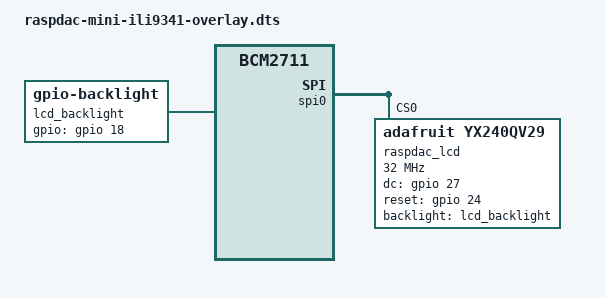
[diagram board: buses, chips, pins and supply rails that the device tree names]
/dts-v1/;
/plugin/;

/*
 * Audiophonics RaspDAC Mini - ILI9341
 * Raspberry Pi 4 / Raspberry Pi OS Trixie / DRM-KMS
 *
 * Wiring assumed:
 *   SPI bus : SPI0
 *   CS      : CE0 / GPIO8
 *   MOSI    : GPIO10
 *   SCLK    : GPIO11
 *   DC      : GPIO27
 *   RESET   : GPIO24
 *
 * Backlight: the LCD "LED" pin is hardwired to 3V3 on the HAT, so there is
 * no software control out of the box. To make it controllable, do the
 * hardware mod: cut the LED->3V3 trace on the HAT and wire the LCD "LED"
 * pin to GPIO18 (physical pin 12). The gpio-backlight node below then
 * creates /sys/class/backlight/lcd_backlight and the DRM core switches the
 * backlight off automatically when the output is blanked (wlopm --off).
 *
 * The in-kernel DRM tiny ILI9341 driver matches "adafruit,yx240qv29".
 * rotation = <90> gives a 320x240 logical landscape display.
 */

/ {
    compatible = "brcm,bcm2711";

    fragment@0 {
        target = <&spi0>;
        __overlay__ {
            status = "okay";

            #address-cells = <1>;
            #size-cells = <0>;

            raspdac_lcd: display@0 {
                compatible = "adafruit,yx240qv29", "ilitek,ili9341";
                reg = <0>;

                spi-max-frequency = <32000000>;

                dc-gpios = <&gpio 27 0>;
                reset-gpios = <&gpio 24 0>;
                backlight = <&lcd_backlight>;

                rotation = <90>;

                status = "okay";
            };
        };
    };

    fragment@1 {
        target = <&spidev0>;
        __overlay__ {
            status = "disabled";
        };
    };

    fragment@2 {
        target-path = "/";
        __overlay__ {
            lcd_backlight: backlight@0 {
                compatible = "gpio-backlight";
                gpios = <&gpio 18 GPIO_ACTIVE_HIGH>;
                default-on;
                status = "okay";
            };
        };
    };

    __overrides__ {
        speed = <&raspdac_lcd>,"spi-max-frequency:0";
        rotate = <&raspdac_lcd>,"rotation:0";
    };
};

